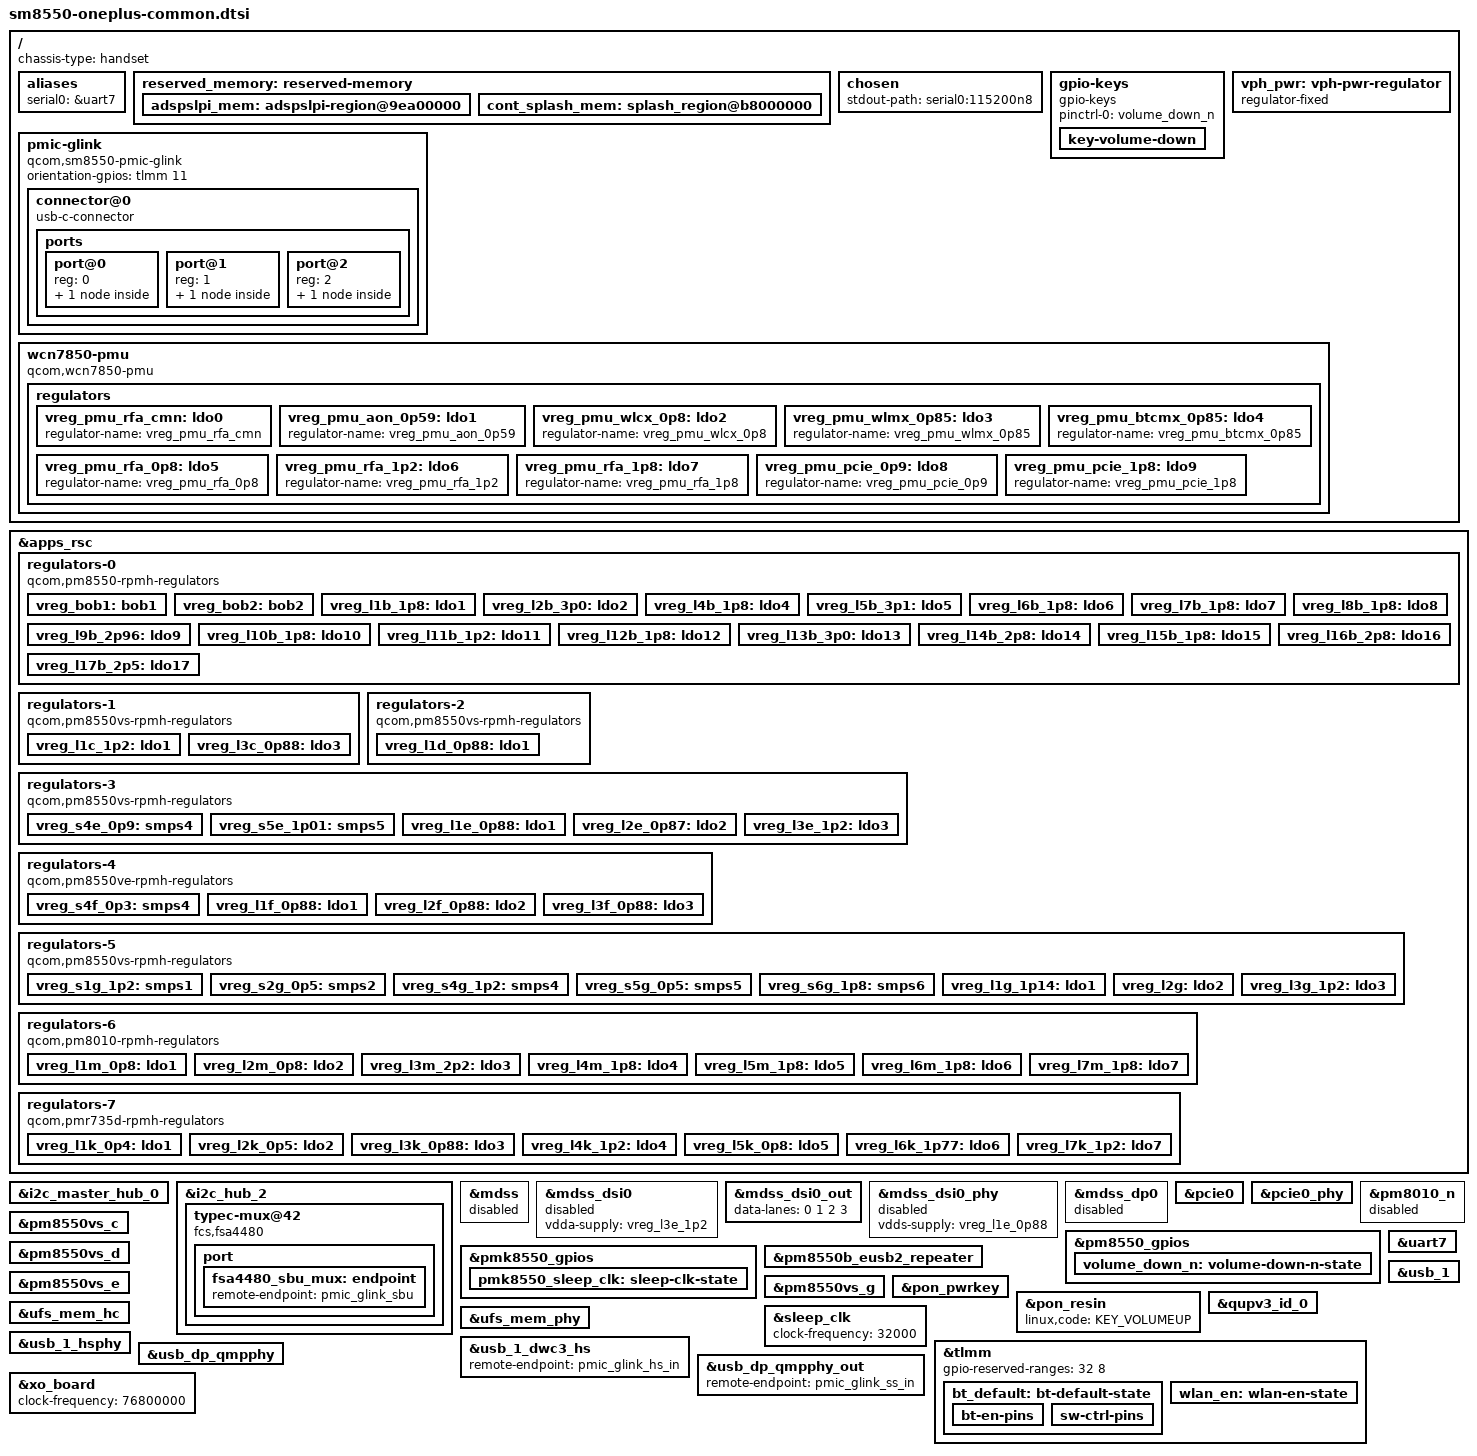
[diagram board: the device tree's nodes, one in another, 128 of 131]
// SPDX-License-Identifier: BSD-3-Clause
/*
 * Copyright (c) 2022, Linaro Limited
 * Copyright (c) 2026, inferno0230 <mail@inferno0230.in>
 */

#include <dt-bindings/regulator/qcom,rpmh-regulator.h>
#include "sm8550.dtsi"
#include "pm8010.dtsi"
#include "pm8550.dtsi"
#include "pm8550b.dtsi"
#define PMK8550VE_SID 5
#include "pm8550ve.dtsi"
#include "pm8550vs.dtsi"
#include "pmk8550.dtsi"
#include "pmr735d_a.dtsi"

/delete-node/ &adspslpi_mem;

/ {
	chassis-type = "handset";

	aliases {
		serial0 = &uart7;
	};

	reserved_memory: reserved-memory {
		/* The ADSP firmware needs ~8MiB more than the SM8550 default. */
		adspslpi_mem: adspslpi-region@9ea00000 {
			reg = <0 0x9ea00000 0 0x4880000>;
			no-map;
		};

		/*
		 * The bootloader turns off the display unless this region is
		 * named exactly "splash_region".
		 */
		cont_splash_mem: splash_region@b8000000 {
			reg = <0 0xb8000000 0 0x2b00000>;
			no-map;
		};
	};

	chosen {
		stdout-path = "serial0:115200n8";
	};

	gpio-keys {
		compatible = "gpio-keys";
		pinctrl-0 = <&volume_down_n>;
		pinctrl-names = "default";

		key-volume-down {
			label = "Volume Down";
			linux,code = <KEY_VOLUMEDOWN>;
			gpios = <&pm8550_gpios 6 GPIO_ACTIVE_LOW>;
			debounce-interval = <15>;
			linux,can-disable;
			wakeup-source;
		};
	};

	pmic-glink {
		compatible = "qcom,sm8550-pmic-glink", "qcom,pmic-glink";
		#address-cells = <1>;
		#size-cells = <0>;
		orientation-gpios = <&tlmm 11 GPIO_ACTIVE_HIGH>;

		connector@0 {
			compatible = "usb-c-connector";
			reg = <0>;
			power-role = "dual";
			data-role = "dual";

			ports {
				#address-cells = <1>;
				#size-cells = <0>;

				port@0 {
					reg = <0>;

					pmic_glink_hs_in: endpoint {
						remote-endpoint = <&usb_1_dwc3_hs>;
					};
				};

				port@1 {
					reg = <1>;

					pmic_glink_ss_in: endpoint {
						remote-endpoint = <&usb_dp_qmpphy_out>;
					};
				};

				port@2 {
					reg = <2>;

					pmic_glink_sbu: endpoint {
						remote-endpoint = <&fsa4480_sbu_mux>;
					};
				};
			};
		};
	};

	vph_pwr: vph-pwr-regulator {
		compatible = "regulator-fixed";
		regulator-name = "vph_pwr";
		regulator-min-microvolt = <3700000>;
		regulator-max-microvolt = <3700000>;

		regulator-always-on;
		regulator-boot-on;
	};

    // Copy from sm8550-qrd
	wcn7850-pmu {
		compatible = "qcom,wcn7850-pmu";

		pinctrl-names = "default";
		pinctrl-0 = <&wlan_en>, <&bt_default>, <&pmk8550_sleep_clk>;

		wlan-enable-gpios = <&tlmm 80 GPIO_ACTIVE_HIGH>;
		bt-enable-gpios = <&tlmm 81 GPIO_ACTIVE_HIGH>;

		vdd-supply = <&vreg_s5g_0p5>;
		vddio-supply = <&vreg_l15b_1p8>;
		vddaon-supply = <&vreg_s2g_0p5>;
		vdddig-supply = <&vreg_s4e_0p9>;
		vddrfa1p2-supply = <&vreg_s4g_1p2>;
		vddrfa1p8-supply = <&vreg_s6g_1p8>;

		regulators {
			vreg_pmu_rfa_cmn: ldo0 {
				regulator-name = "vreg_pmu_rfa_cmn";
			};

			vreg_pmu_aon_0p59: ldo1 {
				regulator-name = "vreg_pmu_aon_0p59";
			};

			vreg_pmu_wlcx_0p8: ldo2 {
				regulator-name = "vreg_pmu_wlcx_0p8";
			};

			vreg_pmu_wlmx_0p85: ldo3 {
				regulator-name = "vreg_pmu_wlmx_0p85";
			};

			vreg_pmu_btcmx_0p85: ldo4 {
				regulator-name = "vreg_pmu_btcmx_0p85";
			};

			vreg_pmu_rfa_0p8: ldo5 {
				regulator-name = "vreg_pmu_rfa_0p8";
			};

			vreg_pmu_rfa_1p2: ldo6 {
				regulator-name = "vreg_pmu_rfa_1p2";
			};

			vreg_pmu_rfa_1p8: ldo7 {
				regulator-name = "vreg_pmu_rfa_1p8";
			};

			vreg_pmu_pcie_0p9: ldo8 {
				regulator-name = "vreg_pmu_pcie_0p9";
			};

			vreg_pmu_pcie_1p8: ldo9 {
				regulator-name = "vreg_pmu_pcie_1p8";
			};
		};
	};
};

&apps_rsc {
	regulators-0 {
		compatible = "qcom,pm8550-rpmh-regulators";
		qcom,pmic-id = "b";

		vdd-bob1-supply = <&vph_pwr>;
		vdd-bob2-supply = <&vph_pwr>;
		vdd-l1-l4-l10-supply = <&vreg_s6g_1p8>;
		vdd-l2-l13-l14-supply = <&vreg_bob1>;
		vdd-l3-supply = <&vreg_s4g_1p2>;
		vdd-l5-l16-supply = <&vreg_bob1>;
		vdd-l6-l7-supply = <&vreg_bob1>;
		vdd-l8-l9-supply = <&vreg_bob1>;
		vdd-l11-supply = <&vreg_s4g_1p2>;
		vdd-l12-supply = <&vreg_s6g_1p8>;
		vdd-l15-supply = <&vreg_s6g_1p8>;
		vdd-l17-supply = <&vreg_bob2>;

		vreg_bob1: bob1 {
			regulator-name = "vreg_bob1";
			regulator-min-microvolt = <3008000>;
			regulator-max-microvolt = <3960000>;
			regulator-initial-mode = <RPMH_REGULATOR_MODE_HPM>;
		};

		vreg_bob2: bob2 {
			regulator-name = "vreg_bob2";
			regulator-min-microvolt = <2704000>;
			regulator-max-microvolt = <3008000>;
			regulator-initial-mode = <RPMH_REGULATOR_MODE_HPM>;
		};

		vreg_l1b_1p8: ldo1 {
			regulator-name = "vreg_l1b_1p8";
			regulator-min-microvolt = <1800000>;
			regulator-max-microvolt = <1800000>;
			regulator-initial-mode = <RPMH_REGULATOR_MODE_HPM>;
		};

		vreg_l2b_3p0: ldo2 {
			regulator-name = "vreg_l2b_3p0";
			regulator-min-microvolt = <3008000>;
			regulator-max-microvolt = <3008000>;
			regulator-initial-mode = <RPMH_REGULATOR_MODE_HPM>;
		};

		vreg_l4b_1p8: ldo4 {
			regulator-name = "vreg_l4b_1p8";
			regulator-min-microvolt = <1800000>;
			regulator-max-microvolt = <1800000>;
			regulator-initial-mode = <RPMH_REGULATOR_MODE_HPM>;
		};

		vreg_l5b_3p1: ldo5 {
			regulator-name = "vreg_l5b_3p1";
			regulator-min-microvolt = <3104000>;
			regulator-max-microvolt = <3104000>;
			regulator-initial-mode = <RPMH_REGULATOR_MODE_HPM>;
		};

		vreg_l6b_1p8: ldo6 {
			regulator-name = "vreg_l6b_1p8";
			regulator-min-microvolt = <1800000>;
			regulator-max-microvolt = <3008000>;
			regulator-initial-mode = <RPMH_REGULATOR_MODE_HPM>;
		};

		vreg_l7b_1p8: ldo7 {
			regulator-name = "vreg_l7b_1p8";
			regulator-min-microvolt = <1800000>;
			regulator-max-microvolt = <3008000>;
			regulator-initial-mode = <RPMH_REGULATOR_MODE_HPM>;
		};

		vreg_l8b_1p8: ldo8 {
			regulator-name = "vreg_l8b_1p8";
			regulator-min-microvolt = <1800000>;
			regulator-max-microvolt = <1800000>;
			regulator-initial-mode = <RPMH_REGULATOR_MODE_HPM>;
			regulator-always-on;
			regulator-boot-on;
		};

		vreg_l9b_2p96: ldo9 {
			regulator-name = "vreg_l9b_2p96";
			regulator-min-microvolt = <2960000>;
			regulator-max-microvolt = <3008000>;
			regulator-initial-mode = <RPMH_REGULATOR_MODE_HPM>;
		};

		vreg_l10b_1p8: ldo10 {
			regulator-name = "vreg_l10b_1p8";
			regulator-min-microvolt = <1800000>;
			regulator-max-microvolt = <1800000>;
			regulator-initial-mode = <RPMH_REGULATOR_MODE_HPM>;
			regulator-always-on;
		};

		vreg_l11b_1p2: ldo11 {
			regulator-name = "vreg_l11b_1p2";
			regulator-min-microvolt = <1200000>;
			regulator-max-microvolt = <1504000>;
			regulator-initial-mode = <RPMH_REGULATOR_MODE_HPM>;
		};

		vreg_l12b_1p8: ldo12 {
			regulator-name = "vreg_l12b_1p8";
			regulator-min-microvolt = <1800000>;
			regulator-max-microvolt = <1800000>;
			regulator-initial-mode = <RPMH_REGULATOR_MODE_HPM>;
		};

		vreg_l13b_3p0: ldo13 {
			regulator-name = "vreg_l13b_3p0";
			regulator-min-microvolt = <3000000>;
			regulator-max-microvolt = <3200000>;
			regulator-initial-mode = <RPMH_REGULATOR_MODE_HPM>;
		};

		vreg_l14b_2p8: ldo14 {
			regulator-name = "vreg_l14b_2p8";
			regulator-min-microvolt = <2800000>;
			regulator-max-microvolt = <3200000>;
			regulator-initial-mode = <RPMH_REGULATOR_MODE_HPM>;
		};

		vreg_l15b_1p8: ldo15 {
			regulator-name = "vreg_l15b_1p8";
			regulator-min-microvolt = <1800000>;
			regulator-max-microvolt = <1800000>;
			regulator-initial-mode = <RPMH_REGULATOR_MODE_HPM>;
			/* regulator-always-on; */
		};

		vreg_l16b_2p8: ldo16 {
			regulator-name = "vreg_l16b_2p8";
			regulator-min-microvolt = <2800000>;
			regulator-max-microvolt = <2800000>;
			regulator-initial-mode = <RPMH_REGULATOR_MODE_HPM>;
		};

		vreg_l17b_2p5: ldo17 {
			regulator-name = "vreg_l17b_2p5";
			regulator-min-microvolt = <2504000>;
			regulator-max-microvolt = <2504000>;
			regulator-initial-mode = <RPMH_REGULATOR_MODE_HPM>;
		};
	};

	regulators-1 {
		compatible = "qcom,pm8550vs-rpmh-regulators";
		qcom,pmic-id = "c";

		vdd-l3-supply = <&vreg_s4e_0p9>;

		vreg_l1c_1p2: ldo1 {
			regulator-name = "vreg_l1c_1p2";
			regulator-min-microvolt = <1200000>;
			regulator-max-microvolt = <1200000>;
			regulator-initial-mode = <RPMH_REGULATOR_MODE_HPM>;
		};

		vreg_l3c_0p88: ldo3 {
			regulator-name = "vreg_l3c_0p88";
			regulator-min-microvolt = <880000>;
			regulator-max-microvolt = <912000>;
			regulator-initial-mode = <RPMH_REGULATOR_MODE_HPM>;
		};
	};

	regulators-2 {
		compatible = "qcom,pm8550vs-rpmh-regulators";
		qcom,pmic-id = "d";

		vdd-l1-supply = <&vreg_s4e_0p9>;

		vreg_l1d_0p88: ldo1 {
			regulator-name = "vreg_l1d_0p88";
			regulator-min-microvolt = <880000>;
			regulator-max-microvolt = <920000>;
			regulator-initial-mode = <RPMH_REGULATOR_MODE_HPM>;
		};
	};

	regulators-3 {
		compatible = "qcom,pm8550vs-rpmh-regulators";
		qcom,pmic-id = "e";

		vdd-l1-supply = <&vreg_s4e_0p9>;
		vdd-l2-supply = <&vreg_s4e_0p9>;
		vdd-l3-supply = <&vreg_s4g_1p2>;
		vdd-s4-supply = <&vph_pwr>;
		vdd-s5-supply = <&vph_pwr>;

		vreg_s4e_0p9: smps4 {
			regulator-name = "vreg_s4e_0p9";
			regulator-min-microvolt = <904000>;
			regulator-max-microvolt = <984000>;
			regulator-initial-mode = <RPMH_REGULATOR_MODE_HPM>;
		};

		vreg_s5e_1p01: smps5 {
			regulator-name = "vreg_s5e_1p01";
			regulator-min-microvolt = <1010000>;
			regulator-max-microvolt = <1120000>;
			regulator-initial-mode = <RPMH_REGULATOR_MODE_HPM>;
		};

		vreg_l1e_0p88: ldo1 {
			regulator-name = "vreg_l1e_0p88";
			regulator-min-microvolt = <880000>;
			regulator-max-microvolt = <912000>;
			regulator-initial-mode = <RPMH_REGULATOR_MODE_HPM>;
		};

		vreg_l2e_0p87: ldo2 {
			regulator-name = "vreg_l2e_0p87";
			regulator-min-microvolt = <870000>;
			regulator-max-microvolt = <970000>;
			regulator-initial-mode = <RPMH_REGULATOR_MODE_HPM>;
		};

		vreg_l3e_1p2: ldo3 {
			regulator-name = "vreg_l3e_1p2";
			regulator-min-microvolt = <1200000>;
			regulator-max-microvolt = <1200000>;
			regulator-initial-mode = <RPMH_REGULATOR_MODE_HPM>;
		};
	};

	regulators-4 {
		compatible = "qcom,pm8550ve-rpmh-regulators";
		qcom,pmic-id = "f";

		vdd-l1-supply = <&vreg_s4e_0p9>;
		vdd-l2-supply = <&vreg_s4e_0p9>;
		vdd-l3-supply = <&vreg_s4e_0p9>;
		vdd-s4-supply = <&vph_pwr>;

		vreg_s4f_0p3: smps4 {
			regulator-name = "vreg_s4f_0p3";
			regulator-min-microvolt = <300000>;
			regulator-max-microvolt = <700000>;
			regulator-initial-mode = <RPMH_REGULATOR_MODE_HPM>;
		};

		vreg_l1f_0p88: ldo1 {
			regulator-name = "vreg_l1f_0p88";
			regulator-min-microvolt = <880000>;
			regulator-max-microvolt = <912000>;
			regulator-initial-mode = <RPMH_REGULATOR_MODE_HPM>;
		};

		vreg_l2f_0p88: ldo2 {
			regulator-name = "vreg_l2f_0p88";
			regulator-min-microvolt = <880000>;
			regulator-max-microvolt = <912000>;
			regulator-initial-mode = <RPMH_REGULATOR_MODE_HPM>;
		};

		vreg_l3f_0p88: ldo3 {
			regulator-name = "vreg_l3f_0p88";
			regulator-min-microvolt = <880000>;
			regulator-max-microvolt = <912000>;
			regulator-initial-mode = <RPMH_REGULATOR_MODE_HPM>;
		};
	};

	regulators-5 {
		compatible = "qcom,pm8550vs-rpmh-regulators";
		qcom,pmic-id = "g";

		vdd-l1-supply = <&vreg_s4g_1p2>;
		vdd-l2-supply = <&vreg_s4g_1p2>;
		vdd-l3-supply = <&vreg_s4g_1p2>;
		vdd-s1-supply = <&vph_pwr>;
		vdd-s2-supply = <&vph_pwr>;
		vdd-s3-supply = <&vph_pwr>;
		vdd-s4-supply = <&vph_pwr>;
		vdd-s5-supply = <&vph_pwr>;
		vdd-s6-supply = <&vph_pwr>;

		vreg_s1g_1p2: smps1 {
			regulator-name = "vreg_s1g_1p2";
			regulator-min-microvolt = <1200000>;
			regulator-max-microvolt = <1300000>;
			regulator-initial-mode = <RPMH_REGULATOR_MODE_HPM>;
		};

		vreg_s2g_0p5: smps2 {
			regulator-name = "vreg_s2g_0p5";
			regulator-min-microvolt = <500000>;
			regulator-max-microvolt = <1036000>;
			regulator-initial-mode = <RPMH_REGULATOR_MODE_HPM>;
		};

		vreg_s4g_1p2: smps4 {
			regulator-name = "vreg_s4g_1p2";
			regulator-min-microvolt = <1200000>;
			regulator-max-microvolt = <1352000>;
			regulator-initial-mode = <RPMH_REGULATOR_MODE_HPM>;
		};

		vreg_s5g_0p5: smps5 {
			regulator-name = "vreg_s5g_0p5";
			regulator-min-microvolt = <500000>;
			regulator-max-microvolt = <1004000>;
			regulator-initial-mode = <RPMH_REGULATOR_MODE_HPM>;
		};

		vreg_s6g_1p8: smps6 {
			regulator-name = "vreg_s6g_1p8";
			regulator-min-microvolt = <1800000>;
			regulator-max-microvolt = <2000000>;
			regulator-initial-mode = <RPMH_REGULATOR_MODE_HPM>;
		};

		vreg_l1g_1p14: ldo1 {
			regulator-name = "vreg_l1g_1p14";
			regulator-min-microvolt = <1144000>;
			regulator-max-microvolt = <1256000>;
			regulator-initial-mode = <RPMH_REGULATOR_MODE_HPM>;
		};

        // aston will override this to 1.05v
		vreg_l2g: ldo2 {
			regulator-name = "vreg_l2g_1p1";
			regulator-min-microvolt = <1100000>;
			regulator-max-microvolt = <1200000>;
			regulator-initial-mode = <RPMH_REGULATOR_MODE_HPM>;
		};

		vreg_l3g_1p2: ldo3 {
			regulator-name = "vreg_l3g_1p2";
			regulator-min-microvolt = <1200000>;
			regulator-max-microvolt = <1200000>;
			regulator-initial-mode = <RPMH_REGULATOR_MODE_HPM>;
		};
	};

	regulators-6 {
		compatible = "qcom,pm8010-rpmh-regulators";
		qcom,pmic-id = "m";

		vdd-l1-l2-supply = <&vreg_s4g_1p2>;
		vdd-l3-l4-supply = <&vreg_bob2>;
		vdd-l5-supply = <&vreg_s6g_1p8>;
		vdd-l6-supply = <&vreg_s6g_1p8>;
		vdd-l7-supply = <&vreg_bob1>;

		vreg_l1m_0p8: ldo1 {
			regulator-name = "vreg_l1m_0p8";
			regulator-min-microvolt = <800000>;
			regulator-max-microvolt = <1200000>;
			regulator-initial-mode = <RPMH_REGULATOR_MODE_HPM>;
		};

		vreg_l2m_0p8: ldo2 {
			regulator-name = "vreg_l2m_0p8";
			regulator-min-microvolt = <800000>;
			regulator-max-microvolt = <1200000>;
			regulator-initial-mode = <RPMH_REGULATOR_MODE_HPM>;
		};

		vreg_l3m_2p2: ldo3 {
			regulator-name = "vreg_l3m_2p2";
			regulator-min-microvolt = <2200000>;
			regulator-max-microvolt = <3304000>;
			regulator-initial-mode = <RPMH_REGULATOR_MODE_HPM>;
		};

		vreg_l4m_1p8: ldo4 {
			regulator-name = "vreg_l4m_1p8";
			regulator-min-microvolt = <1800000>;
			regulator-max-microvolt = <3304000>;
			regulator-initial-mode = <RPMH_REGULATOR_MODE_HPM>;
		};

		vreg_l5m_1p8: ldo5 {
			regulator-name = "vreg_l5m_1p8";
			regulator-min-microvolt = <1800000>;
			regulator-max-microvolt = <1800000>;
			regulator-initial-mode = <RPMH_REGULATOR_MODE_HPM>;
		};

		vreg_l6m_1p8: ldo6 {
			regulator-name = "vreg_l6m_1p8";
			regulator-min-microvolt = <1800000>;
			regulator-max-microvolt = <3304000>;
			regulator-initial-mode = <RPMH_REGULATOR_MODE_HPM>;
		};

		vreg_l7m_1p8: ldo7 {
			regulator-name = "vreg_l7m_1p8";
			regulator-min-microvolt = <1800000>;
			regulator-max-microvolt = <3152000>;
			regulator-initial-mode = <RPMH_REGULATOR_MODE_HPM>;
		};
	};

	regulators-7 {
		compatible = "qcom,pmr735d-rpmh-regulators";
		qcom,pmic-id = "k";

		vdd-l1-l2-l5-supply = <&vreg_s2g_0p5>;
		vdd-l3-l4-supply = <&vreg_s1g_1p2>;
		vdd-l6-supply  = <&vreg_s6g_1p8>;
		vdd-l7-supply = <&vreg_s1g_1p2>;

		vreg_l1k_0p4: ldo1 {
			regulator-name = "vreg_l1k_0p4";
			regulator-min-microvolt = <400000>;
			regulator-max-microvolt = <900000>;
			regulator-initial-mode = <RPMH_REGULATOR_MODE_HPM>;
		};

		vreg_l2k_0p5: ldo2 {
			regulator-name = "vreg_l2k_0p5";
			regulator-min-microvolt = <500000>;
			regulator-max-microvolt = <900000>;
			regulator-initial-mode = <RPMH_REGULATOR_MODE_HPM>;
		};

		vreg_l3k_0p88: ldo3 {
			regulator-name = "vreg_l3k_0p88";
			regulator-min-microvolt = <880000>;
			regulator-max-microvolt = <912000>;
			regulator-initial-mode = <RPMH_REGULATOR_MODE_HPM>;
		};

		vreg_l4k_1p2: ldo4 {
			regulator-name = "vreg_l4k_1p2";
			regulator-min-microvolt = <1200000>;
			regulator-max-microvolt = <1200000>;
			regulator-initial-mode = <RPMH_REGULATOR_MODE_HPM>;
		};

		vreg_l5k_0p8: ldo5 {
			regulator-name = "vreg_l5k_0p8";
			regulator-min-microvolt = <800000>;
			regulator-max-microvolt = <800000>;
			regulator-initial-mode = <RPMH_REGULATOR_MODE_HPM>;
		};

		vreg_l6k_1p77: ldo6 {
			regulator-name = "vreg_l6k_1p77";
			regulator-min-microvolt = <1776000>;
			regulator-max-microvolt = <1900000>;
			regulator-initial-mode = <RPMH_REGULATOR_MODE_HPM>;
		};

		vreg_l7k_1p2: ldo7 {
			regulator-name = "vreg_l7k_1p2";
			regulator-min-microvolt = <1200000>;
			regulator-max-microvolt = <1200000>;
			regulator-initial-mode = <RPMH_REGULATOR_MODE_HPM>;
		};
	};
};

&i2c_master_hub_0 {
	status = "okay";
};

&i2c_hub_2 {
	status = "okay";

	typec-mux@42 {
		compatible = "fcs,fsa4480";
		reg = <0x42>;

		vcc-supply = <&vreg_bob1>;

		mode-switch;
		orientation-switch;

		port {
			fsa4480_sbu_mux: endpoint {
				remote-endpoint = <&pmic_glink_sbu>;
			};
		};
	};
};

&mdss {
	status = "disabled";
};

&mdss_dsi0 {
	vdda-supply = <&vreg_l3e_1p2>;
	status = "disabled";
};

&mdss_dsi0_out {
	data-lanes = <0 1 2 3>;
};

&mdss_dsi0_phy {
	vdds-supply = <&vreg_l1e_0p88>;
	status = "disabled";
};

&mdss_dp0 {
	status = "disabled";
};

&pcie0 {
	wake-gpios = <&tlmm 96 GPIO_ACTIVE_HIGH>;
	perst-gpios = <&tlmm 94 GPIO_ACTIVE_LOW>;

	pinctrl-names = "default";
	pinctrl-0 = <&pcie0_default_state>;

	status = "okay";
};

&pcie0_phy {
	vdda-phy-supply = <&vreg_l1e_0p88>;
	vdda-pll-supply = <&vreg_l3e_1p2>;

	status = "okay";
};

&pm8010_n {
	status = "disabled";
};

&pm8550_gpios {
	volume_down_n: volume-down-n-state {
		pins = "gpio6";
		function = "normal";
		power-source = <1>;
		bias-pull-up;
		input-enable;
	};
};

&pmk8550_gpios {
	pmk8550_sleep_clk: sleep-clk-state {
		pins = "gpio3";
		function = "func1";
		input-disable;
		output-enable;
		bias-disable;
		power-source = <0>;
	};
};

&pm8550b_eusb2_repeater {
	vdd18-supply = <&vreg_l15b_1p8>;
	vdd3-supply = <&vreg_l5b_3p1>;
};

&pm8550vs_c {
	status = "okay";
};

&pm8550vs_d {
	status = "okay";
};

&pm8550vs_e {
	status = "okay";
};

&pm8550vs_g {
	status = "okay";
};

&pon_pwrkey {
	status = "okay";
};

&pon_resin {
	linux,code = <KEY_VOLUMEUP>;
	status = "okay";
};

&qupv3_id_0 {
	status = "okay";
};

&sleep_clk {
	clock-frequency = <32000>;
};

&tlmm {
	gpio-reserved-ranges = <32 8>;

	bt_default: bt-default-state {
		bt-en-pins {
			pins = "gpio81";
			function = "gpio";
			drive-strength = <16>;
			bias-disable;
		};

		sw-ctrl-pins {
			pins = "gpio82";
			function = "gpio";
			bias-pull-down;
		};
	};

	wlan_en: wlan-en-state {
		pins = "gpio80";
		function = "gpio";
		drive-strength = <8>;
		bias-pull-down;
	};
};

&uart7 {
	status = "okay";
};

&ufs_mem_hc {
	reset-gpios = <&tlmm 210 GPIO_ACTIVE_LOW>;
	vcc-supply = <&vreg_l17b_2p5>;
	vcc-max-microamp = <1300000>;
	vccq-supply = <&vreg_l1g_1p14>;
	vccq-max-microamp = <1200000>;
	vdd-hba-supply = <&vreg_l3g_1p2>;

	status = "okay";
};

&ufs_mem_phy {
	vdda-phy-supply = <&vreg_l1d_0p88>;
	vdda-pll-supply = <&vreg_l3e_1p2>;

	status = "okay";
};

&usb_1 {
	status = "okay";
};

&usb_1_dwc3_hs {
	remote-endpoint = <&pmic_glink_hs_in>;
};

&usb_1_hsphy {
	vdd-supply = <&vreg_l1e_0p88>;
	vdda12-supply = <&vreg_l3e_1p2>;

	phys = <&pm8550b_eusb2_repeater>;

	status = "okay";
};

&usb_dp_qmpphy {
	vdda-phy-supply = <&vreg_l3e_1p2>;
	vdda-pll-supply = <&vreg_l3f_0p88>;

	status = "okay";
};

&usb_dp_qmpphy_out {
	remote-endpoint = <&pmic_glink_ss_in>;
};

&xo_board {
	clock-frequency = <76800000>;
};
